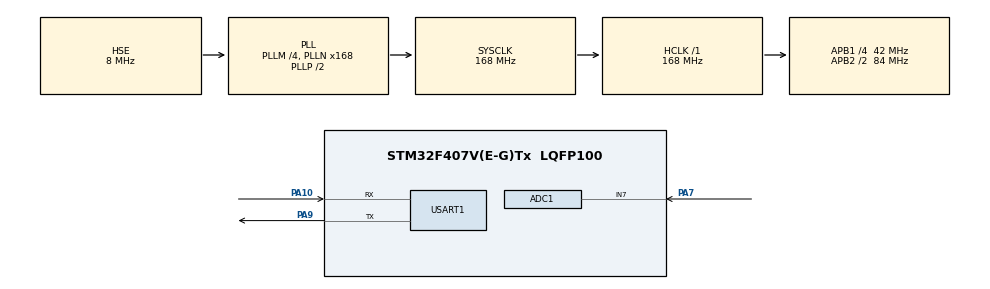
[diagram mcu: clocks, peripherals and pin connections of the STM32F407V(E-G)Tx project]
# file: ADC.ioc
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ADC1.Channel-1\#ChannelRegularConversion=ADC_CHANNEL_7
ADC1.NbrOfConversionFlag=1
ADC1.Rank-1\#ChannelRegularConversion=1
ADC1.SamplingTime-1\#ChannelRegularConversion=ADC_SAMPLETIME_3CYCLES
ADC1.master=1
Mcu.Family=STM32F4
Mcu.Name=STM32F407V(E-G)Tx
Mcu.Package=LQFP100
NVIC.ADC_IRQn=true\:0\:0\:false\:false\:true\:true\:true
NVIC.PriorityGroup=NVIC_PRIORITYGROUP_4
NVIC.USART1_IRQn=true\:1\:0\:true\:false\:true\:true\:true
PA10.Mode=Asynchronous
PA10.Signal=USART1_RX
PA13.Mode=Serial_Wire
PA13.Signal=SYS_JTMS-SWDIO
PA14.Mode=Serial_Wire
PA14.Signal=SYS_JTCK-SWCLK
PA7.Signal=ADCx_IN7
PA9.Mode=Asynchronous
PA9.Signal=USART1_TX
PH0-OSC_IN.Mode=HSE-External-Oscillator
PH0-OSC_IN.Signal=RCC_OSC_IN
PH1-OSC_OUT.Mode=HSE-External-Oscillator
PH1-OSC_OUT.Signal=RCC_OSC_OUT
ProjectManager.HeapSize=0x200
ProjectManager.StackSize=0x400
ProjectManager.TargetToolchain=MDK-ARM V5
RCC.48MHZClocksFreq_Value=84000000
RCC.AHBFreq_Value=168000000
RCC.APB1CLKDivider=RCC_HCLK_DIV4
RCC.APB1Freq_Value=42000000
RCC.APB1TimFreq_Value=84000000
RCC.APB2CLKDivider=RCC_HCLK_DIV2
RCC.APB2Freq_Value=84000000
RCC.APB2TimFreq_Value=168000000
RCC.CortexFreq_Value=168000000
RCC.HCLKFreq_Value=168000000
RCC.HSE_VALUE=8000000
RCC.HSI_VALUE=16000000
RCC.LSE_VALUE=32768
RCC.PLLM=4
RCC.PLLN=168
RCC.PLLSourceVirtual=RCC_PLLSOURCE_HSE
RCC.SYSCLKFreq_VALUE=168000000
RCC.SYSCLKSource=RCC_SYSCLKSOURCE_PLLCLK
RCC.VCOOutputFreq_Value=336000000
SH.ADCx_IN7.0=ADC1_IN7,IN7
USART1.VirtualMode=VM_ASYNC
board=custom

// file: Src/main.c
/* USER CODE BEGIN Header */
/**
  ******************************************************************************
  * @file           : main.c
  * @brief          : Main program body
  ******************************************************************************
  * @attention
  *
  * <h2><center>&copy; Copyright (c) 2021 STMicroelectronics.
  * All rights reserved.</center></h2>
  *
  * This software component is licensed by ST under BSD 3-Clause license,
  * the "License"; You may not use this file except in compliance with the
  * License. You may obtain a copy of the License at:
  *                        opensource.org/licenses/BSD-3-Clause
  *
  ******************************************************************************
  */
/* USER CODE END Header */

#include "main.h"
#include "adc.h"
#include "usart.h"
#include "gpio.h"

/* USER CODE BEGIN Includes */
#include "lcd.h"
#include "lcd_init.h"
#include "stdio.h"
#include "spi.h"
#include "pic.h"
/* USER CODE END Includes */

/* USER CODE BEGIN PD */
int fputc(int ch, FILE *f)
{
  HAL_UART_Transmit(&huart1, (uint8_t *)&ch, 1, 0xffff);
  return ch;
}
/* USER CODE END PD */

/* USER CODE BEGIN PM */
uint16_t  ADC1_Value;
uint16_t  ADC1_Volt;
float     ADC1_Volt1;
/* USER CODE END PM */

/* USER CODE BEGIN PV */
void HAL_ADC_ConvCpltCallback(ADC_HandleTypeDef* hadc)
{
    if(hadc->Instance == ADC1)
    {

	float percent_1;
	int   percent_2;

	ADC1_Value = HAL_ADC_GetValue(&hadc1);    //读取ADC转换结果
	ADC1_Volt = ADC1_Value * 330/ 4096;      //将采样值换算成电压值
    ADC1_Volt1= (ADC1_Volt/100) + (0.1*((ADC1_Volt%100)/10)) + (0.01*(ADC1_Volt%10));

	 LCD_ShowChinese(10,20,"采样值",BLACK,YELLOW,16,0);
	 LCD_ShowChar(65,20,':',BLACK,YELLOW,16,0);
	 LCD_ShowIntNum(74,20,ADC1_Value,4,BLACK,YELLOW,16);

	 LCD_ShowChinese(10,50,"电压值",BLACK,YELLOW,16,0);
	 LCD_ShowChar(65,50,':',BLACK,YELLOW,16,0);
	 LCD_ShowFloatNum1(78,50,ADC1_Volt1,3,BLACK,YELLOW,16);

	 percent_1=ADC1_Volt1/1.90;
	 percent_2=percent_1*100;

	 //LCD_ShowFloatNum1(30,90,percent_1,3,BLACK,YELLOW,16);
	 LCD_ShowIntNum(30,90,percent_2,3,BLACK,YELLOW,16);
     LCD_ShowChar(60,90,'%',BLACK,YELLOW,16,0);

	if(75<percent_2&&percent_2<=100)
	{
		LCD_ShowPicture(10,90,16,8,power1);
	}else if(50<percent_2&&percent_2<=75)
	{
	    LCD_ShowPicture(10,90,16,8,power2);
	}else if (25<percent_2&&percent_2<=50)
	{
		LCD_ShowPicture(10,90,16,8,power3);
	}else if (0<percent_2&&percent_2<=25)
	{
		LCD_ShowPicture(10,90,16,8,power4);
	}

     //LCD_ShowPicture(10,90,16,8,power);
     //	printf("采样值：%d\r\n",ADC1_Value);
//	printf("电压值：%d.%d%d，%.2f\r\n",ADC1_Volt/100,(ADC1_Volt%100)/10,ADC1_Volt%10,ADC1_Volt1);
    }
}
/* USER CODE END PV */

void SystemClock_Config(void);

int main(void)
{

  /* MCU Configuration--------------------------------------------------------*/

  /* Reset of all peripherals, Initializes the Flash interface and the Systick. */
  HAL_Init();

  /* Configure the system clock */
  SystemClock_Config();

  /* Initialize all configured peripherals */
  MX_GPIO_Init();
  MX_ADC1_Init();
  MX_USART1_UART_Init();
  /* USER CODE BEGIN 2 */
  SOFT_SPI_Init();
  LCD_Init();
  LCD_Fill(0,0,128,160,YELLOW);

  /* USER CODE END 2 */

  /* Infinite loop */
  /* USER CODE BEGIN WHILE */
  while (1)
  {
	   HAL_ADC_Start_IT(&hadc1);

//     LCD_ShowChinese(10,20,"采样值",BLACK,YELLOW,16,0);
//	 LCD_ShowChar(65,20,':',BLACK,YELLOW,16,0);
//	 LCD_ShowIntNum(74,20,ADC1_Value,3,BLACK,YELLOW,16);
//
//	 LCD_ShowChinese(10,50,"电压值",BLACK,YELLOW,16,0);
//	 LCD_ShowChar(65,50,':',BLACK,YELLOW,16,0);
//	 LCD_ShowFloatNum1(78,50,ADC1_Volt,3,BLACK,YELLOW,16);

	  HAL_Delay(500);
    /* USER CODE END WHILE */

  }
}

void SystemClock_Config(void)
{
  RCC_OscInitTypeDef RCC_OscInitStruct = {0};
  RCC_ClkInitTypeDef RCC_ClkInitStruct = {0};

  /** Configure the main internal regulator output voltage
  */
  __HAL_RCC_PWR_CLK_ENABLE();
  __HAL_PWR_VOLTAGESCALING_CONFIG(PWR_REGULATOR_VOLTAGE_SCALE1);
  /** Initializes the CPU, AHB and APB busses clocks
  */
  RCC_OscInitStruct.OscillatorType = RCC_OSCILLATORTYPE_HSE;
  RCC_OscInitStruct.HSEState = RCC_HSE_ON;
  RCC_OscInitStruct.PLL.PLLState = RCC_PLL_ON;
  RCC_OscInitStruct.PLL.PLLSource = RCC_PLLSOURCE_HSE;
  RCC_OscInitStruct.PLL.PLLM = 4;
  RCC_OscInitStruct.PLL.PLLN = 168;
  RCC_OscInitStruct.PLL.PLLP = RCC_PLLP_DIV2;
  RCC_OscInitStruct.PLL.PLLQ = 4;
  if (HAL_RCC_OscConfig(&RCC_OscInitStruct) != HAL_OK)
  {
    Error_Handler();
  }
  /** Initializes the CPU, AHB and APB busses clocks
  */
  RCC_ClkInitStruct.ClockType = RCC_CLOCKTYPE_HCLK|RCC_CLOCKTYPE_SYSCLK
                              |RCC_CLOCKTYPE_PCLK1|RCC_CLOCKTYPE_PCLK2;
  RCC_ClkInitStruct.SYSCLKSource = RCC_SYSCLKSOURCE_PLLCLK;
  RCC_ClkInitStruct.AHBCLKDivider = RCC_SYSCLK_DIV1;
  RCC_ClkInitStruct.APB1CLKDivider = RCC_HCLK_DIV4;
  RCC_ClkInitStruct.APB2CLKDivider = RCC_HCLK_DIV2;

  if (HAL_RCC_ClockConfig(&RCC_ClkInitStruct, FLASH_LATENCY_5) != HAL_OK)
  {
    Error_Handler();
  }
}

void Error_Handler(void)
{
}

/************************ (C) COPYRIGHT STMicroelectronics *****END OF FILE****/
